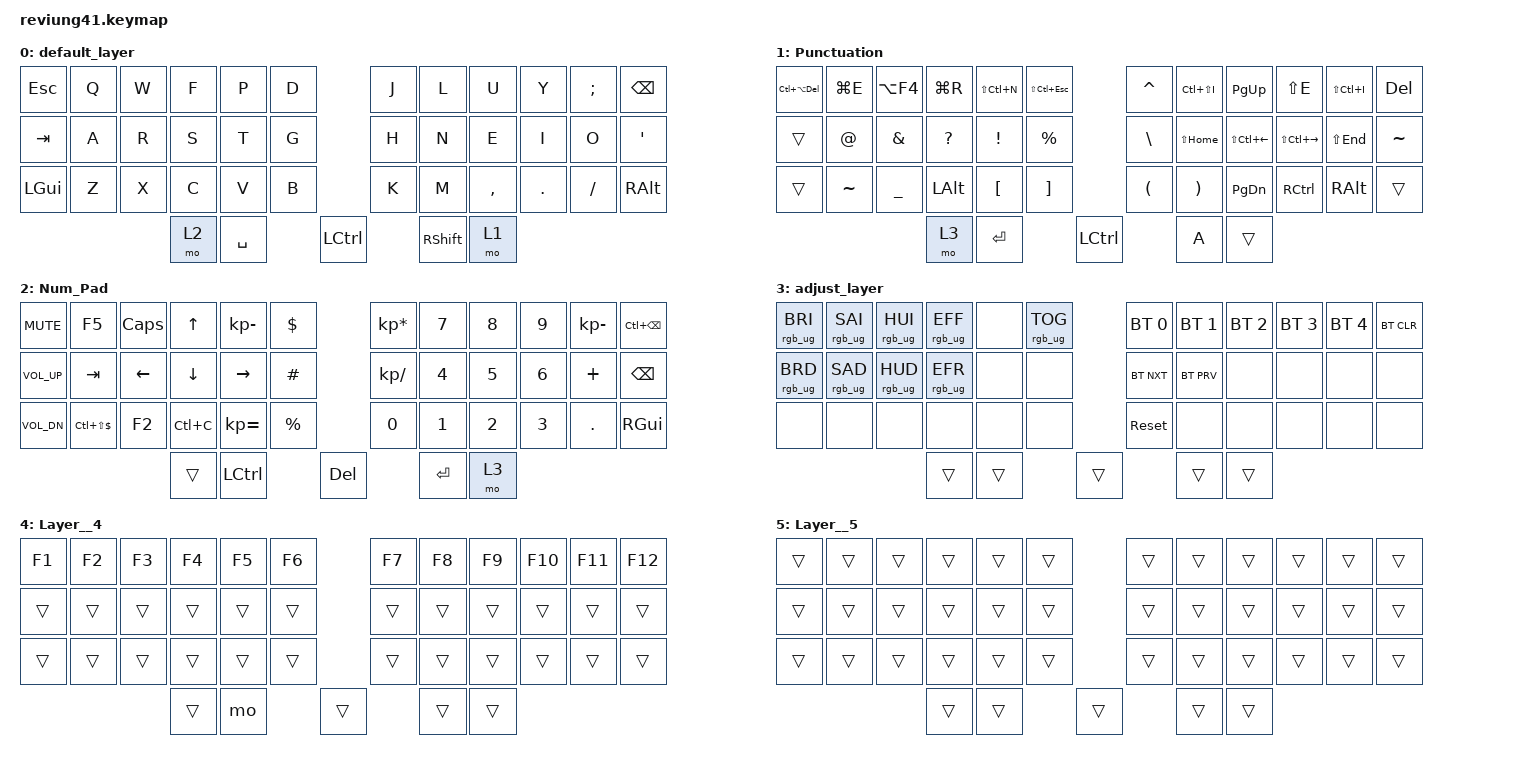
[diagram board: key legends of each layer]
/*
 * Copyright (c) 2020 The ZMK Contributors
 *
 * SPDX-License-Identifier: MIT
 */

#include <behaviors.dtsi>
#include <dt-bindings/zmk/bt.h>
#include <dt-bindings/zmk/keys.h>
#include <dt-bindings/zmk/rgb.h>

/ {
    combos { compatible = "zmk,combos"; };

    keymap {
        compatible = "zmk,keymap";

        default_layer {
            // -------------------------------------------------------------------------------------
            // |  TAB |  Q  |  W  |  E  |  R  |  T  |   |  Y  |  U   |  I  |  O  |  P  |   BKSP    |
            // | CTRL |  A  |  S  |  D  |  F  |  G  |   |  H  |  J   |  K  |  L  |  ;  |    '      |
            // | SHFT |  Z  |  X  |  C  |  V  |  B  |   |  N  |  M   |  ,  |  .  |  /  | SHFT(RET) |
            //                         | ALT | LWR | SPC | RSE  | ALT |

            bindings = <
&kp ESC       &kp Q  &kp W  &kp F  &kp P      &kp D                    &kp J  &kp L            &kp U      &kp Y    &kp SEMI  &kp BACKSPACE
&kp TAB       &kp A  &kp R  &kp S  &kp T      &kp G                    &kp H  &kp N            &kp E      &kp I    &kp O     &kp SQT
&kp LEFT_GUI  &kp Z  &kp X  &kp C  &kp V      &kp B                    &kp K  &kp M            &kp COMMA  &kp DOT  &kp FSLH  &kp RIGHT_ALT
                            &mo 2  &kp SPACE         &kp LEFT_CONTROL         &kp RIGHT_SHIFT  &mo 1
            >;
        };

        Punctuation {
            // ----------------------------------------------------------------------------------
            // |    |  !  |  @  |  #  |  $  |  %  |   |  ^  |  &  |  *  |  (  |  )  |    DEL    |
            // |    |  _  |  +  |  {  |  }  | "|" |   | LFT | DWN |  UP | RGT |  `  |     ~     |
            // |    | ESC | GUI | ALT | CAPS|  "  |   | HOME| END | PGUP| PGDN| PRSC| SHFT(RET) |
            //                       |     |     | RET | ADJ |     |

            bindings = <
&kp LC(LA(DEL))  &kp LG(E)  &kp LA(F4)     &kp LG(R)     &kp LS(LC(N))     &kp LS(LC(ESC))                      &kp CARET             &kp LC(LS(I))          &kp PG_UP         &kp LS(E)          &kp LS(LC(I))  &kp DEL
&trans           &kp AT     &kp AMPERSAND  &kp QUESTION  &kp EXCL          &kp PERCENT                          &kp BACKSLASH         &kp LS(HOME)           &kp LS(LC(LEFT))  &kp LS(LC(RIGHT))  &kp LS(END)    &kp TILDE
&trans           &kp TILDE  &kp UNDER      &kp LALT      &kp LEFT_BRACKET  &kp RIGHT_BRACKET                    &kp LEFT_PARENTHESIS  &kp RIGHT_PARENTHESIS  &kp PAGE_DOWN     &kp RIGHT_CONTROL  &kp RIGHT_ALT  &trans
                                           &mo 3         &kp ENTER                            &kp LEFT_CONTROL                        &kp A                  &trans
            >;
        };

        Num_Pad {
            // -----------------------------------------------------------------------------------------
            // |    |  1  |  2  |  3  |  4  |  5  |   |  6  |  7  |  8  |  9  |  0  | DEL |
            // |    |  -  |  =  |  [  |  ]  |  \  |   | F1  | F2  | F3  | F4  | F5  | F6  |
            // |    | ESC | GUI | ALT | CAPS|  "  |   | F7  | F8  | F9  | F10 | F11 | F12 |
            //                       |     | ADJ | BKSP |    |     |

            bindings = <
&kp C_MUTE    &kp F5              &kp CAPS  &kp UP     &kp KP_MINUS      &kp DOLLAR               &kp KP_MULTIPLY  &kp NUMBER_7  &kp NUMBER_8  &kp NUMBER_9  &kp KP_MINUS  &kp LC(BACKSPACE)
&kp C_VOL_UP  &kp TAB             &kp LEFT  &kp DOWN   &kp RIGHT         &kp HASH                 &kp KP_DIVIDE    &kp NUMBER_4  &kp NUMBER_5  &kp NUMBER_6  &kp PLUS      &kp BACKSPACE
&kp C_VOL_DN  &kp LC(LS(DOLLAR))  &kp F2    &kp LC(C)  &kp KP_EQUAL      &kp PERCENT              &kp NUMBER_0     &kp NUMBER_1  &kp NUMBER_2  &kp NUMBER_3  &kp PERIOD    &kp RIGHT_GUI
                                            &trans     &kp LEFT_CONTROL               &kp DELETE                   &kp ENTER     &mo 3
            >;
        };

        adjust_layer {
            // -----------------------------------------------------------------------------------------
            // | RGB BRI+ | RGB SAT+ | RGB HUE+ | RGB ANI+ |    | RGB TOG |   |  BT1  | BT2 | BT3 | BT4 | BT5 | BT CLR |
            // | RGB BRI- | RGB SAT- | RGB HUE- | RGB ANI- |    |         |   |       |     |     |     |     |        |
            // |          |          |          |          |    |         |   | RESET |     |     |     |     |        |
            //                                              |     |     |     |     |     |

            bindings = <
&rgb_ug RGB_BRI  &rgb_ug RGB_SAI  &rgb_ug RGB_HUI  &rgb_ug RGB_EFF  &none   &rgb_ug RGB_TOG          &bt BT_SEL 0  &bt BT_SEL 1  &bt BT_SEL 2  &bt BT_SEL 3  &bt BT_SEL 4  &bt BT_CLR
&rgb_ug RGB_BRD  &rgb_ug RGB_SAD  &rgb_ug RGB_HUD  &rgb_ug RGB_EFR  &none   &none                    &bt BT_NXT    &bt BT_PRV    &none         &none         &none         &none
&none            &none            &none            &none            &none   &none                    &sys_reset    &none         &none         &none         &none         &none
                                                   &trans           &trans                   &trans                &trans        &trans
            >;
        };

        Layer__4 {
            bindings = <
&kp F1  &kp F2  &kp F3  &kp F4  &kp F5  &kp F6          &kp F7  &kp F8  &kp F9  &kp F10  &kp F11  &kp F12
&trans  &trans  &trans  &trans  &trans  &trans          &trans  &trans  &trans  &trans   &trans   &trans
&trans  &trans  &trans  &trans  &trans  &trans          &trans  &trans  &trans  &trans   &trans   &trans
                        &trans  &mo             &trans          &trans  &trans
            >;
        };

        Layer__5 {
            bindings = <
&trans  &trans  &trans  &trans  &trans  &trans          &trans  &trans  &trans  &trans  &trans  &trans
&trans  &trans  &trans  &trans  &trans  &trans          &trans  &trans  &trans  &trans  &trans  &trans
&trans  &trans  &trans  &trans  &trans  &trans          &trans  &trans  &trans  &trans  &trans  &trans
                        &trans  &trans          &trans          &trans  &trans
            >;
        };
    };
};
